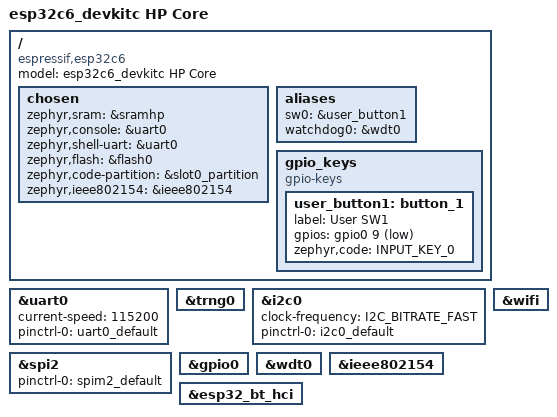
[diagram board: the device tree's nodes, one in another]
/*
 * Copyright (c) 2023 Espressif Systems (Shanghai) Co., Ltd.
 *
 * SPDX-License-Identifier: Apache-2.0
 */

/dts-v1/;

#include <espressif/esp32c6/esp32c6_wroom_n8.dtsi>
#include "esp32c6_devkitc_hpcore-pinctrl.dtsi"
#include <zephyr/dt-bindings/input/input-event-codes.h>
#include <espressif/partitions_0x0_default.dtsi>

/ {
	compatible = "espressif,esp32c6";
	model = "esp32c6_devkitc HP Core";

	chosen {
		zephyr,sram = &sramhp;
		zephyr,console = &uart0;
		zephyr,shell-uart = &uart0;
		zephyr,flash = &flash0;
		zephyr,code-partition = &slot0_partition;
		zephyr,ieee802154 = &ieee802154;
	};

	aliases {
		sw0 = &user_button1;
		watchdog0 = &wdt0;
	};

	gpio_keys {
		compatible = "gpio-keys";

		user_button1: button_1 {
			label = "User SW1";
			gpios = <&gpio0 9 (GPIO_PULL_UP | GPIO_ACTIVE_LOW)>;
			zephyr,code = <INPUT_KEY_0>;
		};
	};
};

&uart0 {
	current-speed = <115200>;
	pinctrl-0 = <&uart0_default>;
	pinctrl-names = "default";
	status = "okay";
};

&trng0 {
	status = "okay";
};

&i2c0 {
	clock-frequency = <I2C_BITRATE_FAST>;
	pinctrl-0 = <&i2c0_default>;
	pinctrl-names = "default";
	status = "okay";
};

&spi2 {
	#address-cells = <1>;
	#size-cells = <0>;
	pinctrl-0 = <&spim2_default>;
	pinctrl-names = "default";
	status = "okay";
};

&gpio0 {
	status = "okay";
};

&wdt0 {
	status = "okay";
};

&wifi {
	status = "okay";
};

&ieee802154 {
	status = "okay";
};

&esp32_bt_hci {
	status = "okay";
};
